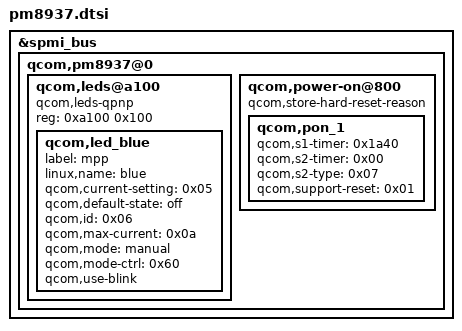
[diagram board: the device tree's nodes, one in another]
&spmi_bus {
	qcom,pm8937@0 {
		qcom,leds@a100 {
			compatible = "qcom,leds-qpnp";
			reg = <0xa100 0x100>;

			qcom,led_blue {
				label = "mpp";
				linux,name = "blue";
				qcom,current-setting = <0x05>;
				qcom,default-state = "off";
				qcom,id = <0x06>;
				qcom,max-current = <0x0a>;
				qcom,mode = "manual";
				qcom,mode-ctrl = <0x60>;
				qcom,use-blink;
			};
		};
		qcom,power-on@800 {
			qcom,store-hard-reset-reason;
			qcom,pon_1 {
				qcom,s1-timer = < 0x1a40 >;
				qcom,s2-timer = < 0x00 >;
				qcom,s2-type = < 0x07 >;
				qcom,support-reset = < 0x01 >;
			};
		};
	};
};
